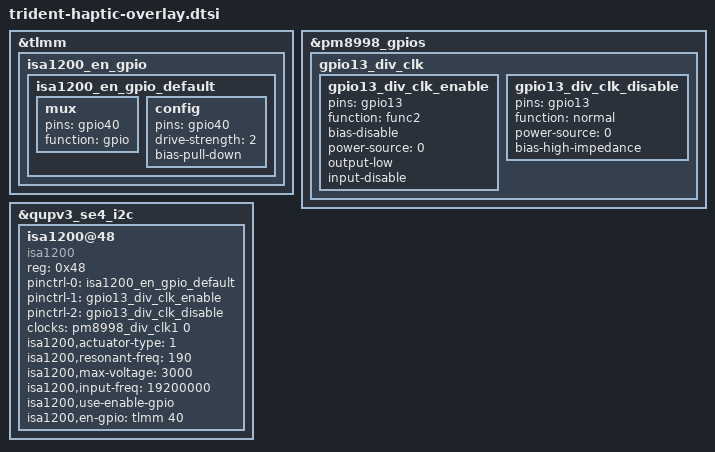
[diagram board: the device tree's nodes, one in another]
/*
 * Copyright (c) 2018, The Linux Foundation. All rights reserved.
 *
 * This program is free software; you can redistribute it and/or modify
 * it under the terms of the GNU General Public License version 2 and
 * only version 2 as published by the Free Software Foundation.
 *
 * This program is distributed in the hope that it will be useful,
 * but WITHOUT ANY WARRANTY; without even the implied warranty of
 * MERCHANTABILITY or FITNESS FOR A PARTICULAR PURPOSE.  See the
 * GNU General Public License for more details.
 */


&tlmm {
	isa1200_en_gpio {
		isa1200_en_gpio_default: isa1200_en_gpio_default{
			mux {
				pins = "gpio40";
				function = "gpio";
			};

			config {
				pins = "gpio40";
				drive-strength = <2>;
				bias-pull-down;
			};
		};
	};
};

&pm8998_gpios {
	gpio13_div_clk {
		gpio13_div_clk_enable: gpio13_div_clk_enable {
			pins = "gpio13"; /* GPIO 13 */
			function = "func2"; /* special function 2 */
			bias-disable; /* disable pull up & down */
			power-source = <0>;
			output-low; /* digital output, no invert */
			input-disable; /* prevent GPIO from being set to DIO */
		};

		gpio13_div_clk_disable: gpio13_div_clk_disable {
			pins = "gpio13"; /* GPIO 13 */
			function = "normal"; /* normal */
			power-source = <0>;
			bias-high-impedance; /* DISABLE GPIO */
		};
	};
};

&qupv3_se4_i2c {
	status = "okay";

	/*
	 * ISA1200 slave address is 0x48(7bit) as default.
	 */
	isa1200@48 {
		compatible = "isa1200";
		reg = <0x48>;
		pinctrl-names = "default", "enable", "disable";
		pinctrl-0 = <&isa1200_en_gpio_default>;
		pinctrl-1 = <&gpio13_div_clk_enable>;
		pinctrl-2 = <&gpio13_div_clk_disable>;
		clock-names = "isa1200_ext_clk";
		clocks = <&pm8998_div_clk1 0>; /* configure to div_clk1 */
		isa1200,actuator-type = <1>;
		isa1200,resonant-freq = <190>;
		isa1200,max-voltage = <3000>;
		isa1200,input-freq = <19200000>;
		isa1200,use-enable-gpio;
		isa1200,en-gpio = <&tlmm 40 0x00>;
	};
};
